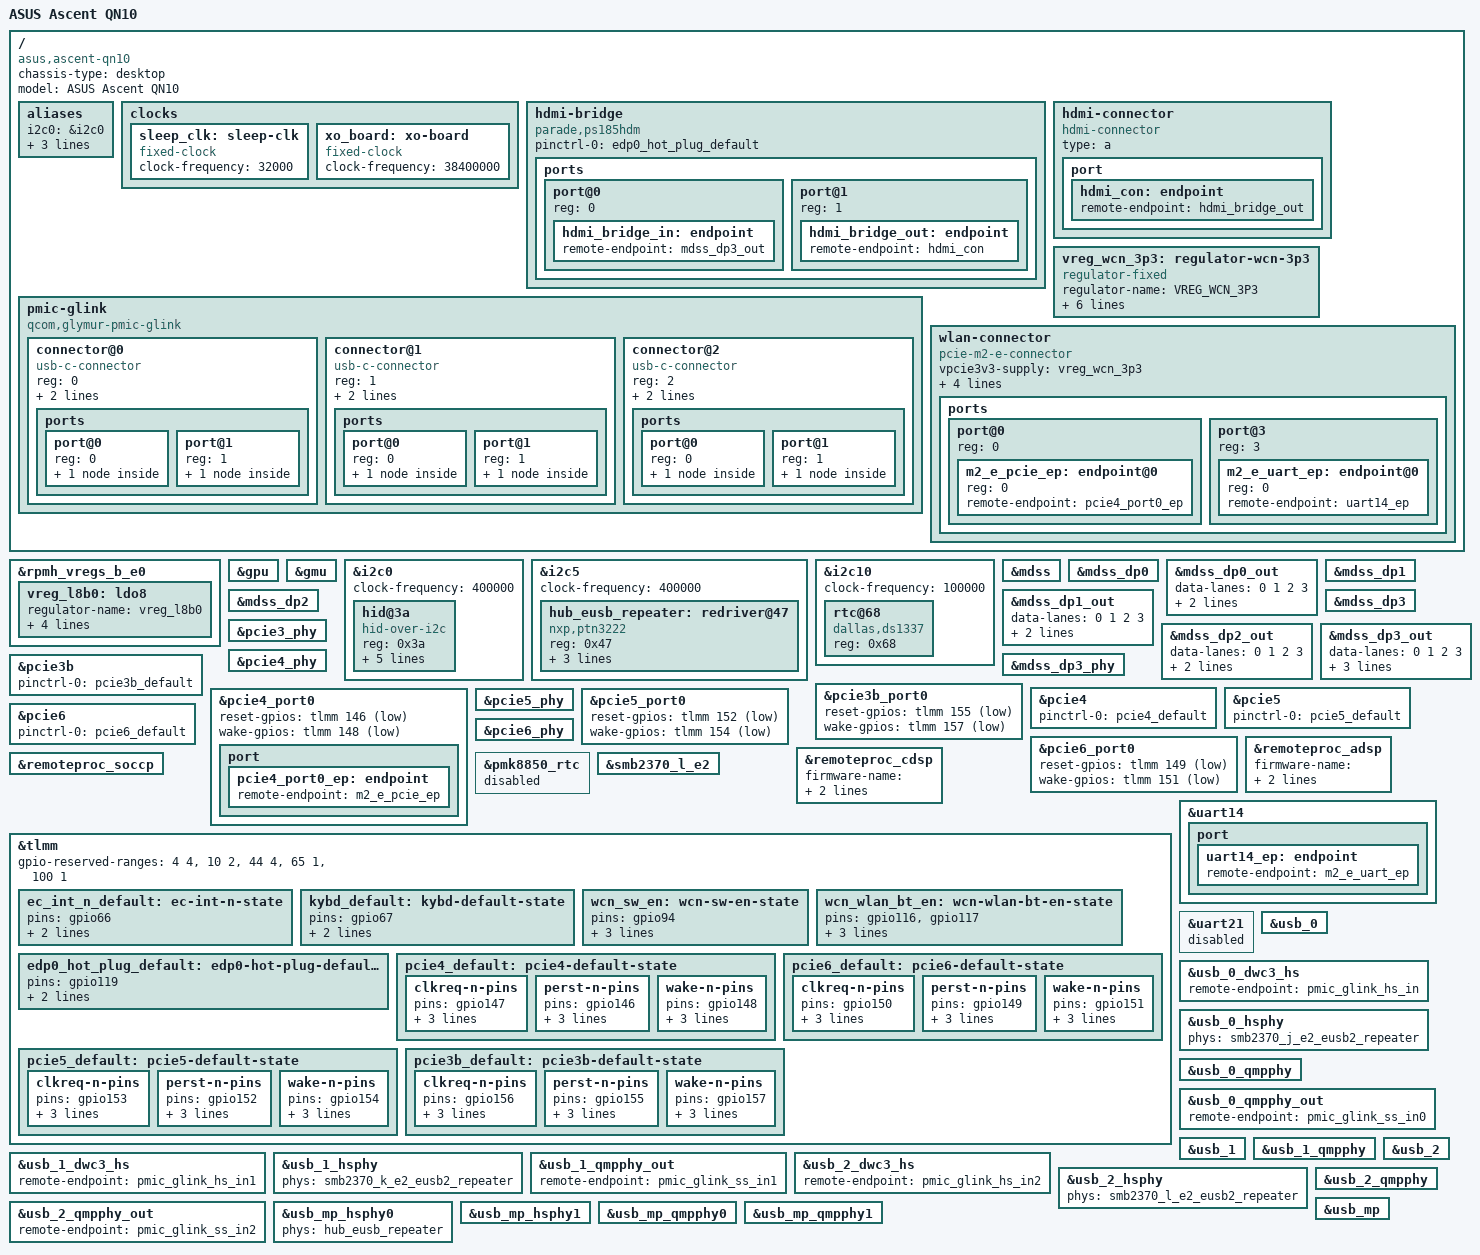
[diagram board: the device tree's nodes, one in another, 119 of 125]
// SPDX-License-Identifier: BSD-3-Clause
/*
 * Copyright (c) Qualcomm Technologies, Inc. and/or its subsidiaries.
 */
/dts-v1/;

#include "glymur-cob.dtsi"

#include <dt-bindings/clock/qcom,rpmh.h>
#include <dt-bindings/gpio/gpio.h>
#include <dt-bindings/regulator/qcom,rpmh-regulator.h>
#include <dt-bindings/pinctrl/qcom,pmic-gpio.h>

/ {
	compatible = "asus,ascent-qn10", "qcom,glymur";
	chassis-type = "desktop";
	model = "ASUS Ascent QN10";

	aliases {
		i2c0 = &i2c0;
		i2c5 = &i2c5;
		i2c10 = &i2c10;
		serial0 = &uart14;
	};

	clocks {
		sleep_clk: sleep-clk {
			compatible = "fixed-clock";
			clock-frequency = <32000>;
			#clock-cells = <0>;
		};

		xo_board: xo-board {
			compatible = "fixed-clock";
			clock-frequency = <38400000>;
			#clock-cells = <0>;
		};
	};

	/* PS195 on eDP0 for HDMI connector. */
	hdmi-bridge {
		compatible = "parade,ps185hdm";

		pinctrl-0 = <&edp0_hot_plug_default>;
		pinctrl-names = "default";

		ports {
			#address-cells = <1>;
			#size-cells = <0>;

			port@0 {
				reg = <0>;

				hdmi_bridge_in: endpoint {
					remote-endpoint = <&mdss_dp3_out>;
				};
			};

			port@1 {
				reg = <1>;

				hdmi_bridge_out: endpoint {
					remote-endpoint = <&hdmi_con>;
				};
			};
		};
	};

	hdmi-connector {
		compatible = "hdmi-connector";
		type = "a";

		port {
			hdmi_con: endpoint {
				remote-endpoint = <&hdmi_bridge_out>;
			};
		};
	};

	pmic-glink {
		compatible = "qcom,glymur-pmic-glink",
			     "qcom,pmic-glink";
		#address-cells = <1>;
		#size-cells = <0>;

		/* Rear Type-C port */
		connector@0 {
			compatible = "usb-c-connector";
			reg = <0>;
			power-role = "dual";
			data-role = "dual";

			ports {
				#address-cells = <1>;
				#size-cells = <0>;

				port@0 {
					reg = <0>;

					pmic_glink_hs_in: endpoint {
						remote-endpoint = <&usb_0_dwc3_hs>;
					};
				};

				port@1 {
					reg = <1>;

					pmic_glink_ss_in0: endpoint {
						remote-endpoint = <&usb_0_qmpphy_out>;
					};
				};
			};
		};

		/* Front left Type-C port */
		connector@1 {
			compatible = "usb-c-connector";
			reg = <1>;
			power-role = "dual";
			data-role = "dual";

			ports {
				#address-cells = <1>;
				#size-cells = <0>;

				port@0 {
					reg = <0>;

					pmic_glink_hs_in1: endpoint {
						remote-endpoint = <&usb_1_dwc3_hs>;
					};
				};

				port@1 {
					reg = <1>;

					pmic_glink_ss_in1: endpoint {
						remote-endpoint = <&usb_1_qmpphy_out>;
					};
				};
			};
		};

		/* Front right Type-C port */
		connector@2 {
			compatible = "usb-c-connector";
			reg = <2>;
			power-role = "dual";
			data-role = "dual";

			ports {
				#address-cells = <1>;
				#size-cells = <0>;

				port@0 {
					reg = <0>;

					pmic_glink_hs_in2: endpoint {
						remote-endpoint = <&usb_2_dwc3_hs>;
					};
				};

				port@1 {
					reg = <1>;

					pmic_glink_ss_in2: endpoint {
						remote-endpoint = <&usb_2_qmpphy_out>;
					};
				};
			};
		};
	};

	vreg_wcn_3p3: regulator-wcn-3p3 {
		compatible = "regulator-fixed";

		regulator-name = "VREG_WCN_3P3";
		regulator-min-microvolt = <3300000>;
		regulator-max-microvolt = <3300000>;

		gpio = <&tlmm 94 GPIO_ACTIVE_HIGH>;
		enable-active-high;

		pinctrl-0 = <&wcn_sw_en>;
		pinctrl-names = "default";

		regulator-boot-on;
	};

	wlan-connector {
		compatible = "pcie-m2-e-connector";
		vpcie3v3-supply = <&vreg_wcn_3p3>;
		vpcie1v8-supply = <&vreg_l15b0>;

		w-disable1-gpios = <&tlmm 117 GPIO_ACTIVE_LOW>;
		w-disable2-gpios = <&tlmm 116 GPIO_ACTIVE_LOW>;

		pinctrl-0 = <&wcn_wlan_bt_en>;
		pinctrl-names = "default";

		ports {
			#address-cells = <1>;
			#size-cells = <0>;

			port@0 {
				reg = <0>;
				#address-cells = <1>;
				#size-cells = <0>;

				m2_e_pcie_ep: endpoint@0 {
					reg = <0>;
					remote-endpoint = <&pcie4_port0_ep>;
				};
			};

			port@3 {
				reg = <3>;
				#address-cells = <1>;
				#size-cells = <0>;

				m2_e_uart_ep: endpoint@0 {
					reg = <0>;
					remote-endpoint = <&uart14_ep>;
				};
			};
		};
	};
};

&rpmh_vregs_b_e0 {
	vreg_l8b0: ldo8 {
		regulator-name = "vreg_l8b0";
		regulator-min-microvolt = <3304000>;
		regulator-max-microvolt = <3304000>;
		regulator-initial-mode = <RPMH_REGULATOR_MODE_HPM>;
	};
};

&gpu {
	status = "okay";
};

&gmu {
	status = "okay";
};

&i2c0 {
	clock-frequency = <400000>;

	status = "okay";

	hid@3a {
		compatible = "hid-over-i2c";
		reg = <0x3a>;

		hid-descr-addr = <0x1>;
		interrupts-extended = <&tlmm 67 IRQ_TYPE_LEVEL_LOW>;

		pinctrl-0 = <&kybd_default>;
		pinctrl-names = "default";

		wakeup-source;
	};
};

&i2c5 {
	clock-frequency = <400000>;

	status = "okay";

	/* PTN3222 on eUSB3, between USB MP0 and the GL3590 hub. */
	hub_eusb_repeater: redriver@47 {
		compatible = "nxp,ptn3222";
		reg = <0x47>;
		vdd3v3-supply = <&vreg_l8b0>;
		vdd1v8-supply = <&vreg_l15b0>;
		reset-gpios = <&tlmm 8 GPIO_ACTIVE_LOW>;
		#phy-cells = <0>;
	};
};

&i2c10 {
	clock-frequency = <100000>;

	status = "okay";

	rtc@68 {
		compatible = "dallas,ds1337";
		reg = <0x68>;
	};
};

&mdss {
	status = "okay";
};

&mdss_dp0 {
	status = "okay";
};

&mdss_dp0_out {
	data-lanes = <0 1 2 3>;
	link-frequencies = /bits/ 64 <1620000000 2700000000 5400000000 8100000000>;
};

&mdss_dp1 {
	status = "okay";
};

&mdss_dp1_out {
	data-lanes = <0 1 2 3>;
	link-frequencies = /bits/ 64 <1620000000 2700000000 5400000000 8100000000>;
};

&mdss_dp2 {
	status = "okay";
};

&mdss_dp2_out {
	data-lanes = <0 1 2 3>;
	link-frequencies = /bits/ 64 <1620000000 2700000000 5400000000 8100000000>;
};

&mdss_dp3 {
	status = "okay";
};

&mdss_dp3_out {
	data-lanes = <0 1 2 3>;
	link-frequencies = /bits/ 64 <1620000000 2700000000 5400000000 8100000000>;

	remote-endpoint = <&hdmi_bridge_in>;
};

&mdss_dp3_phy {
	status = "okay";
};

&pcie3_phy {
	status = "okay";
};

&pcie3b {
	pinctrl-0 = <&pcie3b_default>;
	pinctrl-names = "default";

	status = "okay";
};

&pcie3b_port0 {
	reset-gpios = <&tlmm 155 GPIO_ACTIVE_LOW>;
	wake-gpios = <&tlmm 157 GPIO_ACTIVE_LOW>;
};

&pcie4 {
	pinctrl-0 = <&pcie4_default>;
	pinctrl-names = "default";

	status = "okay";
};

&pcie4_phy {
	status = "okay";
};

&pcie4_port0 {
	reset-gpios = <&tlmm 146 GPIO_ACTIVE_LOW>;
	wake-gpios = <&tlmm 148 GPIO_ACTIVE_LOW>;

	port {
		pcie4_port0_ep: endpoint {
			remote-endpoint = <&m2_e_pcie_ep>;
		};
	};
};

&pcie5 {
	pinctrl-0 = <&pcie5_default>;
	pinctrl-names = "default";

	status = "okay";
};

&pcie5_phy {
	status = "okay";
};

&pcie5_port0 {
	reset-gpios = <&tlmm 152 GPIO_ACTIVE_LOW>;
	wake-gpios = <&tlmm 154 GPIO_ACTIVE_LOW>;
};

/* PCIe6 is wired to the RTL8125BP 2.5GbE controller. */
&pcie6 {
	pinctrl-0 = <&pcie6_default>;
	pinctrl-names = "default";

	status = "okay";
};

&pcie6_phy {
	status = "okay";
};

&pcie6_port0 {
	reset-gpios = <&tlmm 149 GPIO_ACTIVE_LOW>;
	wake-gpios = <&tlmm 151 GPIO_ACTIVE_LOW>;
};

&remoteproc_adsp {
	firmware-name = "qcom/glymur/ASUSTeK/QN10/qcadsp8480.mbn",
			"qcom/glymur/ASUSTeK/QN10/adsp_dtbs.elf";

	status = "okay";
};

&remoteproc_cdsp {
	firmware-name = "qcom/glymur/ASUSTeK/QN10/qccdsp8480.mbn",
			"qcom/glymur/ASUSTeK/QN10/cdsp_dtbs.elf";

	status = "okay";
};

&remoteproc_soccp {
	status = "okay";
};

&pmk8850_rtc {
	status = "disabled";
};

&smb2370_l_e2 {
	status = "okay";
};

&tlmm {
	gpio-reserved-ranges = <4 4>, /* EC Secure */
			       <10 2>, /* OOB UART */
			       <44 4>, /* TPM */
			       <65 1>, /* EC reset */
			       <100 1>; /* Board ID */

	ec_int_n_default: ec-int-n-state {
		pins = "gpio66";
		function = "gpio";
		bias-disable;
	};

	kybd_default: kybd-default-state {
		pins = "gpio67";
		function = "gpio";
		bias-disable;
	};

	wcn_sw_en: wcn-sw-en-state {
		pins = "gpio94";
		function = "gpio";
		drive-strength = <2>;
		bias-disable;
	};

	wcn_wlan_bt_en: wcn-wlan-bt-en-state {
		pins = "gpio116", "gpio117";
		function = "gpio";
		drive-strength = <2>;
		bias-disable;
	};

	edp0_hot_plug_default: edp0-hot-plug-default-state {
		pins = "gpio119";
		function = "edp0_hot";
		bias-disable;
	};

	pcie4_default: pcie4-default-state {
		clkreq-n-pins {
			pins = "gpio147";
			function = "pcie4_clk_req_n";
			drive-strength = <2>;
			bias-pull-up;
		};

		perst-n-pins {
			pins = "gpio146";
			function = "gpio";
			drive-strength = <2>;
			bias-disable;
		};

		wake-n-pins {
			pins = "gpio148";
			function = "gpio";
			drive-strength = <2>;
			bias-pull-up;
		};
	};

	pcie6_default: pcie6-default-state {
		clkreq-n-pins {
			pins = "gpio150";
			function = "pcie6_clk_req_n";
			drive-strength = <2>;
			bias-pull-up;
		};

		perst-n-pins {
			pins = "gpio149";
			function = "gpio";
			drive-strength = <2>;
			bias-disable;
		};

		wake-n-pins {
			pins = "gpio151";
			function = "gpio";
			drive-strength = <2>;
			bias-pull-up;
		};
	};

	pcie5_default: pcie5-default-state {
		clkreq-n-pins {
			pins = "gpio153";
			function = "pcie5_clk_req_n";
			drive-strength = <2>;
			bias-pull-up;
		};

		perst-n-pins {
			pins = "gpio152";
			function = "gpio";
			drive-strength = <2>;
			bias-disable;
		};

		wake-n-pins {
			pins = "gpio154";
			function = "gpio";
			drive-strength = <2>;
			bias-pull-up;
		};
	};

	pcie3b_default: pcie3b-default-state {
		clkreq-n-pins {
			pins = "gpio156";
			function = "pcie3b_clk";
			drive-strength = <2>;
			bias-pull-up;
		};

		perst-n-pins {
			pins = "gpio155";
			function = "gpio";
			drive-strength = <2>;
			bias-disable;
		};

		wake-n-pins {
			pins = "gpio157";
			function = "gpio";
			drive-strength = <2>;
			bias-pull-up;
		};
	};
};

&uart14 {
	status = "okay";

	port {
		uart14_ep: endpoint {
			remote-endpoint = <&m2_e_uart_ep>;
		};
	};
};

&uart21 {
	status = "disabled";
};

&usb_0 {
	status = "okay";
};

&usb_0_dwc3_hs {
	remote-endpoint = <&pmic_glink_hs_in>;
};

&usb_0_hsphy {
	phys = <&smb2370_j_e2_eusb2_repeater>;

	status = "okay";
};

&usb_0_qmpphy {
	status = "okay";
};

&usb_0_qmpphy_out {
	remote-endpoint = <&pmic_glink_ss_in0>;
};

&usb_1 {
	status = "okay";
};

&usb_1_dwc3_hs {
	remote-endpoint = <&pmic_glink_hs_in1>;
};

&usb_1_hsphy {
	phys = <&smb2370_k_e2_eusb2_repeater>;

	status = "okay";
};

&usb_1_qmpphy {
	status = "okay";
};

&usb_1_qmpphy_out {
	remote-endpoint = <&pmic_glink_ss_in1>;
};

&usb_2 {
	status = "okay";
};

&usb_2_dwc3_hs {
	remote-endpoint = <&pmic_glink_hs_in2>;
};

&usb_2_hsphy {
	phys = <&smb2370_l_e2_eusb2_repeater>;

	status = "okay";
};

&usb_2_qmpphy {
	status = "okay";
};

&usb_2_qmpphy_out {
	remote-endpoint = <&pmic_glink_ss_in2>;
};

&usb_mp {
	status = "okay";
};

/* MP0 (eUSB3 + USBSS3) -> GL3590 */
&usb_mp_hsphy0 {
	phys = <&hub_eusb_repeater>;

	status = "okay";
};

/* MP1 (eUSB6 + USBSS4) -> not connected */
&usb_mp_hsphy1 {
	status = "okay";
};

&usb_mp_qmpphy0 {
	status = "okay";
};

&usb_mp_qmpphy1 {
	status = "okay";
};
